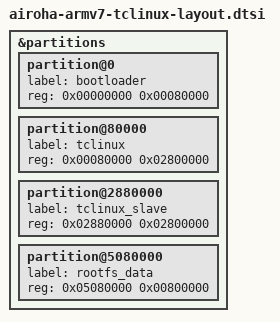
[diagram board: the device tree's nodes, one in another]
&partitions {
    partition@0 {
        label = "bootloader";
        reg = <0x00000000 0x00080000>; /* 512KB */
    };
    partition@80000 {
        label = "tclinux";
        reg = <0x00080000 0x02800000>; /* 40MB */
    };
    partition@2880000 {
        label = "tclinux_slave";
        reg = <0x02880000 0x02800000>; /* 40MB */
    };
    partition@5080000 {
        label = "rootfs_data";
        reg = <0x05080000 0x00800000>; /* 512KB */
    };
};
